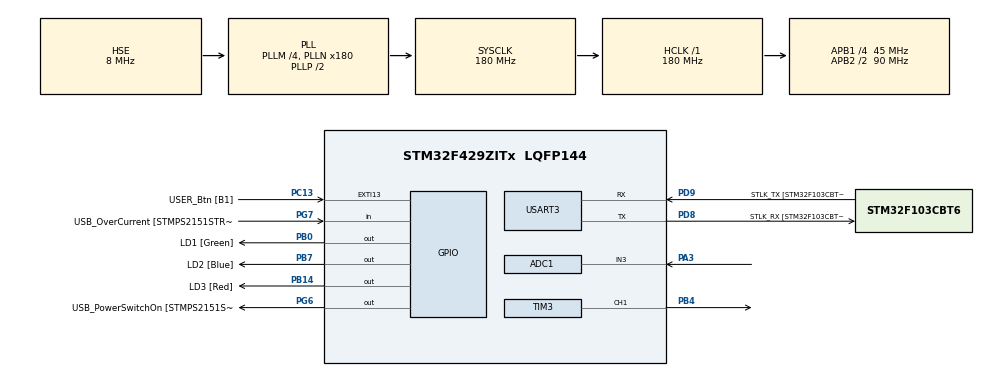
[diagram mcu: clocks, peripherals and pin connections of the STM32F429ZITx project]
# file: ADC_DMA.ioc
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ADC1.Channel-0\#ChannelRegularConversion=ADC_CHANNEL_3
ADC1.ClockPrescaler=ADC_CLOCK_SYNC_PCLK_DIV6
ADC1.ContinuousConvMode=ENABLE
ADC1.DMAContinuousRequests=ENABLE
ADC1.NbrOfConversion=1
ADC1.NbrOfConversionFlag=1
ADC1.Rank-0\#ChannelRegularConversion=1
ADC1.SamplingTime-0\#ChannelRegularConversion=ADC_SAMPLETIME_3CYCLES
ADC1.ScanConvMode=DISABLE
ADC1.master=1
Dma.ADC1.2.Direction=DMA_PERIPH_TO_MEMORY
Dma.ADC1.2.FIFOMode=DMA_FIFOMODE_DISABLE
Dma.ADC1.2.Instance=DMA2_Stream0
Dma.ADC1.2.MemDataAlignment=DMA_MDATAALIGN_HALFWORD
Dma.ADC1.2.MemInc=DMA_MINC_ENABLE
Dma.ADC1.2.Mode=DMA_CIRCULAR
Dma.ADC1.2.PeriphDataAlignment=DMA_PDATAALIGN_HALFWORD
Dma.ADC1.2.PeriphInc=DMA_PINC_DISABLE
Dma.ADC1.2.Priority=DMA_PRIORITY_LOW
Dma.Request0=TIM3_CH1/TRIG
Dma.Request1=TIM3_CH4/UP
Dma.Request2=ADC1
Dma.TIM3_CH1/TRIG.0.Direction=DMA_PERIPH_TO_MEMORY
Dma.TIM3_CH1/TRIG.0.FIFOMode=DMA_FIFOMODE_DISABLE
Dma.TIM3_CH1/TRIG.0.Instance=DMA1_Stream4
Dma.TIM3_CH1/TRIG.0.MemDataAlignment=DMA_MDATAALIGN_HALFWORD
Dma.TIM3_CH1/TRIG.0.MemInc=DMA_MINC_ENABLE
Dma.TIM3_CH1/TRIG.0.Mode=DMA_CIRCULAR
Dma.TIM3_CH1/TRIG.0.PeriphDataAlignment=DMA_PDATAALIGN_HALFWORD
Dma.TIM3_CH1/TRIG.0.PeriphInc=DMA_PINC_DISABLE
Dma.TIM3_CH1/TRIG.0.Priority=DMA_PRIORITY_LOW
Dma.TIM3_CH4/UP.1.Direction=DMA_PERIPH_TO_MEMORY
Dma.TIM3_CH4/UP.1.FIFOMode=DMA_FIFOMODE_DISABLE
Dma.TIM3_CH4/UP.1.Instance=DMA1_Stream2
Dma.TIM3_CH4/UP.1.MemDataAlignment=DMA_MDATAALIGN_HALFWORD
Dma.TIM3_CH4/UP.1.MemInc=DMA_MINC_ENABLE
Dma.TIM3_CH4/UP.1.Mode=DMA_CIRCULAR
Dma.TIM3_CH4/UP.1.PeriphDataAlignment=DMA_PDATAALIGN_HALFWORD
Dma.TIM3_CH4/UP.1.PeriphInc=DMA_PINC_DISABLE
Dma.TIM3_CH4/UP.1.Priority=DMA_PRIORITY_LOW
Mcu.Family=STM32F4
Mcu.Name=STM32F429ZITx
Mcu.Package=LQFP144
NVIC.ADC_IRQn=true\:0\:0\:false\:false\:true\:true\:true\:true
NVIC.DMA1_Stream2_IRQn=true\:0\:0\:false\:false\:true\:false\:true\:true
NVIC.DMA1_Stream4_IRQn=true\:0\:0\:false\:false\:true\:false\:true\:true
NVIC.DMA2_Stream0_IRQn=true\:0\:0\:false\:false\:true\:false\:true\:true
NVIC.PriorityGroup=NVIC_PRIORITYGROUP_4
NVIC.TIM3_IRQn=true\:0\:0\:false\:false\:true\:true\:true\:true
NVIC.USART3_IRQn=true\:0\:0\:false\:false\:true\:true\:true\:true
PA1.GPIO_Label=RMII_REF_CLK [LAN8742A-CZ-TR_REFCLK0]
PA1.Signal=ETH_REF_CLK
PA10.GPIO_Label=USB_ID
PA10.Signal=USB_OTG_FS_ID
PA11.GPIO_Label=USB_DM
PA11.Signal=USB_OTG_FS_DM
PA12.GPIO_Label=USB_DP
PA12.Signal=USB_OTG_FS_DP
PA13.GPIO_Label=TMS
PA13.Mode=Trace_Asynchronous_SW
PA13.Signal=SYS_JTMS-SWDIO
PA14.GPIO_Label=TCK
PA14.Mode=Trace_Asynchronous_SW
PA14.Signal=SYS_JTCK-SWCLK
PA2.GPIO_Label=RMII_MDIO [LAN8742A-CZ-TR_MDIO]
PA2.Signal=ETH_MDIO
PA3.Signal=ADCx_IN3
PA7.GPIO_Label=RMII_CRS_DV [LAN8742A-CZ-TR_CRS_DV]
PA7.Signal=ETH_CRS_DV
PA8.GPIO_Label=USB_SOF [TP1]
PA8.Signal=USB_OTG_FS_SOF
PA9.GPIO_Label=USB_VBUS
PA9.Signal=USB_OTG_FS_VBUS
PB0.GPIO_Label=LD1 [Green]
PB0.Signal=GPIO_Output
PB13.GPIO_Label=RMII_TXD1 [LAN8742A-CZ-TR_TXD1]
PB13.Signal=ETH_TXD1
PB14.GPIO_Label=LD3 [Red]
PB14.Signal=GPIO_Output
PB3.Mode=Trace_Asynchronous_SW
PB3.Signal=SYS_JTDO-SWO
PB4.Signal=S_TIM3_CH1
PB7.GPIO_Label=LD2 [Blue]
PB7.Signal=GPIO_Output
PC1.GPIO_Label=RMII_MDC [LAN8742A-CZ-TR_MDC]
PC1.Signal=ETH_MDC
PC13.GPIO_Label=USER_Btn [B1]
PC13.Signal=GPXTI13
PC14/OSC32_IN.Signal=RCC_OSC32_IN
PC15/OSC32_OUT.Signal=RCC_OSC32_OUT
PC4.GPIO_Label=RMII_RXD0 [LAN8742A-CZ-TR_RXD0]
PC4.Signal=ETH_RXD0
PC5.GPIO_Label=RMII_RXD1 [LAN8742A-CZ-TR_RXD1]
PC5.Signal=ETH_RXD1
PD8.GPIO_Label=STLK_RX [STM32F103CBT6_PA3]
PD8.Mode=Asynchronous
PD8.Signal=USART3_TX
PD9.GPIO_Label=STLK_TX [STM32F103CBT6_PA2]
PD9.Mode=Asynchronous
PD9.Signal=USART3_RX
PG11.GPIO_Label=RMII_TX_EN [LAN8742A-CZ-TR_TXEN]
PG11.Signal=ETH_TX_EN
PG13.GPIO_Label=RMII_TXD0 [LAN8742A-CZ-TR_TXD0]
PG13.Signal=ETH_TXD0
PG6.GPIO_Label=USB_PowerSwitchOn [STMPS2151STR_EN]
PG6.Signal=GPIO_Output
PG7.GPIO_Label=USB_OverCurrent [STMPS2151STR_FAULT]
PG7.Signal=GPIO_Input
PH0/OSC_IN.GPIO_Label=MCO [STM32F103CBT6_PA8]
PH0/OSC_IN.Mode=HSE-External-Oscillator
PH0/OSC_IN.Signal=RCC_OSC_IN
PH1/OSC_OUT.Mode=HSE-External-Oscillator
PH1/OSC_OUT.Signal=RCC_OSC_OUT
ProjectManager.HeapSize=0x200
ProjectManager.StackSize=0x400
ProjectManager.TargetToolchain=STM32CubeIDE
RCC.48MHZClocksFreq_Value=90000000
RCC.AHBFreq_Value=180000000
RCC.APB1CLKDivider=RCC_HCLK_DIV4
RCC.APB1Freq_Value=45000000
RCC.APB1TimFreq_Value=90000000
RCC.APB2CLKDivider=RCC_HCLK_DIV2
RCC.APB2Freq_Value=90000000
RCC.APB2TimFreq_Value=180000000
RCC.CortexFreq_Value=180000000
RCC.HCLKFreq_Value=180000000
RCC.HSE_VALUE=8000000
RCC.HSI_VALUE=16000000
RCC.LSE_VALUE=32768
RCC.PLLM=4
RCC.PLLMUL=RCC_PLL_MUL9
RCC.PLLN=180
RCC.PLLSourceVirtual=RCC_PLLSOURCE_HSE
RCC.PRESCALERUSB=RCC_USBCLKSOURCE_PLL_DIV1_5
RCC.SYSCLKFreq_VALUE=180000000
RCC.SYSCLKSource=RCC_SYSCLKSOURCE_PLLCLK
RCC.SYSCLKSourceVirtual=RCC_SYSCLKSOURCE_PLLCLK
RCC.USBFreq_Value=48000000
RCC.VCOOutputFreq_Value=360000000
SH.ADCx_IN3.0=ADC1_IN3,IN3
SH.S_TIM3_CH1.0=TIM3_CH1,PWM Generation1 CH1
TIM3.Channel-PWM\ Generation1\ CH1=TIM_CHANNEL_1
TIM3.Period=1000-1
TIM3.Prescaler=9-1
TIM3.Pulse-PWM\ Generation1\ CH1=300
USART3.VirtualMode=VM_ASYNC
VP_TIM3_VS_ClockSourceINT.Mode=Internal
board=NUCLEO-F429ZI

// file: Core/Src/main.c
/* USER CODE BEGIN Header */
/**
  ******************************************************************************
  * @file           : main.c
  * @brief          : Main program body
  ******************************************************************************
  * @attention
  *
  * Copyright (c) 2022 STMicroelectronics.
  * All rights reserved.
  *
  * This software is licensed under terms that can be found in the LICENSE file
  * in the root directory of this software component.
  * If no LICENSE file comes with this software, it is provided AS-IS.
  *
  ******************************************************************************
  */
/* USER CODE END Header */
#include "main.h"
#include "adc.h"
#include "dma.h"
#include "tim.h"
#include "usart.h"
#include "gpio.h"

/* USER CODE BEGIN Includes */
#include "stdio.h"
#include "user_def.h"
/* USER CODE END Includes */

void SystemClock_Config(void);
/* USER CODE BEGIN PFP */
int _write(int file, char* p, int len);
/* USER CODE END PFP */

int main(void)
{

  /* MCU Configuration--------------------------------------------------------*/

  /* Reset of all peripherals, Initializes the Flash interface and the Systick. */
  HAL_Init();

  /* Configure the system clock */
  SystemClock_Config();

  /* Initialize all configured peripherals */
  MX_GPIO_Init();
  MX_DMA_Init();
  MX_TIM3_Init();
  MX_USART3_UART_Init();
  MX_ADC1_Init();
  /* USER CODE BEGIN 2 */
  uint16_t adc_val[200];
  uint16_t size = sizeof(adc_val)/sizeof(uint16_t);
  HAL_TIM_PWM_Start(&htim3, TIM_CHANNEL_1);
  HAL_ADC_Start_DMA(&hadc1, (uint32_t *)adc_val, size);

  printf("sizeof array :  %d\r\n", size);

  for(int i=0; i< size; i++)
  {
	  printf("%d\r\n", adc_val[i]);
  }
  DWT_Delay_us(1);
  /* USER CODE END 2 */

  /* Infinite loop */
  /* USER CODE BEGIN WHILE */
  while (1)
  {
//	  for(int i=0; i< sizeof(adc_val); i++)
//	  {
//		  printf("%d\r\n", adc_val[i]);
//	  }
//	  HAL_Delay(100);
    /* USER CODE END WHILE */

  }
}

void SystemClock_Config(void)
{
  RCC_OscInitTypeDef RCC_OscInitStruct = {0};
  RCC_ClkInitTypeDef RCC_ClkInitStruct = {0};

  /** Configure the main internal regulator output voltage
  */
  __HAL_RCC_PWR_CLK_ENABLE();
  __HAL_PWR_VOLTAGESCALING_CONFIG(PWR_REGULATOR_VOLTAGE_SCALE1);

  /** Initializes the RCC Oscillators according to the specified parameters
  * in the RCC_OscInitTypeDef structure.
  */
  RCC_OscInitStruct.OscillatorType = RCC_OSCILLATORTYPE_HSE;
  RCC_OscInitStruct.HSEState = RCC_HSE_ON;
  RCC_OscInitStruct.PLL.PLLState = RCC_PLL_ON;
  RCC_OscInitStruct.PLL.PLLSource = RCC_PLLSOURCE_HSE;
  RCC_OscInitStruct.PLL.PLLM = 4;
  RCC_OscInitStruct.PLL.PLLN = 180;
  RCC_OscInitStruct.PLL.PLLP = RCC_PLLP_DIV2;
  RCC_OscInitStruct.PLL.PLLQ = 4;
  if (HAL_RCC_OscConfig(&RCC_OscInitStruct) != HAL_OK)
  {
    Error_Handler();
  }

  /** Activate the Over-Drive mode
  */
  if (HAL_PWREx_EnableOverDrive() != HAL_OK)
  {
    Error_Handler();
  }

  /** Initializes the CPU, AHB and APB buses clocks
  */
  RCC_ClkInitStruct.ClockType = RCC_CLOCKTYPE_HCLK|RCC_CLOCKTYPE_SYSCLK
                              |RCC_CLOCKTYPE_PCLK1|RCC_CLOCKTYPE_PCLK2;
  RCC_ClkInitStruct.SYSCLKSource = RCC_SYSCLKSOURCE_PLLCLK;
  RCC_ClkInitStruct.AHBCLKDivider = RCC_SYSCLK_DIV1;
  RCC_ClkInitStruct.APB1CLKDivider = RCC_HCLK_DIV4;
  RCC_ClkInitStruct.APB2CLKDivider = RCC_HCLK_DIV2;

  if (HAL_RCC_ClockConfig(&RCC_ClkInitStruct, FLASH_LATENCY_5) != HAL_OK)
  {
    Error_Handler();
  }
}

/* USER CODE BEGIN 4 */
int _write(int file, char* p, int len)
{
	if(HAL_UART_Transmit(&huart3, (uint8_t *)p, len, 10) == HAL_OK) return len;
	else return -1;
}
/* USER CODE END 4 */

void Error_Handler(void)
{
  __disable_irq();
  while (1)
  {
  }
}
